# CC2538NF53 register map
File version: 1.0
CPU: CM3 1.0, other endian, MPU, FPU, 3 interrupt priority bits
Registers are 32-bit, read-write, reset 0x0 unless marked. A register's access mark holds for its fields unless they carry their own. Offsets are from the block's base; [hi:lo] are bit positions; {n}, {i} and the like mark numbered series.

## GPTIMER0 — Register fields should be considered static unless otherwise noted as dynamic.
Base 0x40030000
Same registers: GPTIMER1 0x40031000, GPTIMER2 0x40032000, GPTIMER3 0x40033000
0x00 CFG — GPTM configuration This register configures the global operation of the GPTM. The value written to this register determines whether the GPTM is in 32-bit mode (concatenated timers) or in 16-bit mode (individual, split timers).
  [2:0] GPTMCFG — [2:0] GPTM configuration The GPTMCFG values are defined as follows: 0x0: 32-bit timer configuration. 0x1: 32-bit real-time clock 0x2: Reserved 0x3: Reserved 0x4: 16-bit timer configuration. The function is controlled by bits [1:0] of GPTMTAMR and GPTMTBMR. 0x5-0x7: Reserved
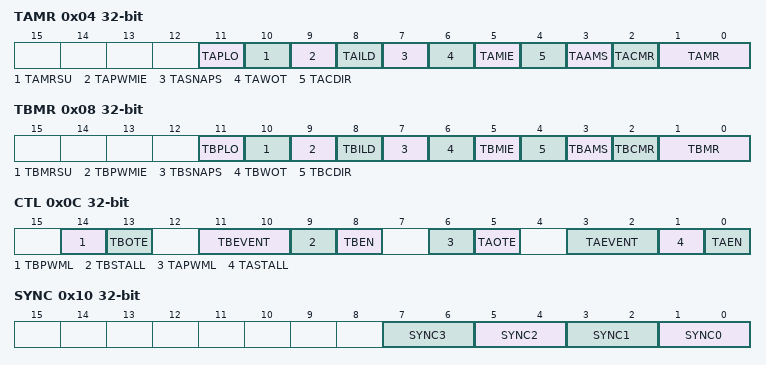
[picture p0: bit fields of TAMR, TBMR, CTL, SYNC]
0x04 TAMR — GPTM Timer A mode This register configures the GPTM based on the configuration selected in the CFG register. This register controls the modes for Timer A when it is used individually. When Timer A and Timer B are concatenated, this register controls the modes for both Timer A and Timer B, and the contents of TBMR are ignored.
  [11] TAPLO — [11:11] Legacy PWM operation 0: Legacy operation 1: CCP is set to 1 on time-out.
  [10] TAMRSU — [10:10] Timer A match register update mode 0: Update GPTMAMATCHR and GPTMAPR if used on the next cycle. 1: Update GPTMAMATCHR and GPTMAPR if used on the next time-out. If the timer is disabled (TAEN is clear) when this bit is set, GPTMTAMATCHR and GPTMTAPR are updated when the timer is enabled. If the timer is stalled (TASTALL is set), GPTMTAMATCHR and GPTMTAPR are updated according to the configuration of this bit.
  [9] TAPWMIE — [9:9] GPTM Timer A PWM interrupt enable This bit enables interrupts in PWM mode on rising, falling, or both edges of the CCP output. 0: Interrupt is disabled. 1: Interrupt is enabled. This bit is valid only in PWM mode.
  [8] TAILD — [8:8] GPTM Timer A PWM interval load write 0: Update the GPTMTAR register with the value in the GPTMTAILR register on the next cycle. If the prescaler is used, update the GPTMTAPS register with the value in the GPTMTAPR register on the next cycle. 1: Update the GPTMTAR register with the value in the GPTMTAILR register on the next cycle. If the prescaler is used, update the GPTMTAPS register with the value in the GPTMTAPR register on the next time-out.
  [7] TASNAPS — [7:7] GPTM Timer A snap-shot mode 0: Snap-shot mode is disabled. 1: If Timer A is configured in periodic mode, the actual free-running value of Timer A is loaded at the time-out event into the GPTM Timer A (GPTMTAR) register.
  [6] TAWOT — [6:6] GPTM Timer A wait-on-trigger 0: Timer A begins counting as soon as it is enabled. 1: If Timer A is enabled (TAEN is set in the GPTMCTL register), Timer A does not begin counting until it receives a trigger from the Timer in the previous position in the daisy-chain. This bit must be clear for GP Timer module 0, Timer A.
  [5] TAMIE — [5:5] GPTM Timer A match interrupt enable 0: The match interrupt is disabled. 1: An interrupt is generated when the match value in the GPTMTAMATCHR register is reached in the one-shot and periodic modes.
  [4] TACDIR — [4:4] GPTM Timer A count direction 0: The timer counts down. 1: The timer counts up. When counting up, the timer starts from a value of 0x0.
  [3] TAAMS — [3:3] GPTM Timer A alternate mode 0: Capture mode is enabled. 1: PWM mode is enabled. Note: To enable PWM mode, the TACM bit must be cleared and the TAMR field must be configured to 0x2.
  [2] TACMR — [2:2] GPTM Timer A capture mode 0: Edge-count mode 1: Edge-time mode
  [1:0] TAMR — [1:0] GPTM Timer A mode 0x0: Reserved 0x1: One-shot mode 0x2: Periodic mode 0x3: Capture mode The timer mode is based on the timer configuration defined by bits [2:0] in the GPTMCFG register.
0x08 TBMR — GPTM Timer B mode This register configures the GPTM based on the configuration selected in the CFG register. This register controls the modes for Timer B when it is used individually. When Timer A and Timer B are concatenated, this register is ignored and TBMR controls the modes for both Timer A and Timer B.
  [11] TBPLO — [11:11] Legacy PWM operation 0: Legacy operation 1: CCP is set to 1 on time-out.
  [10] TBMRSU — [10:10] Timer B match register update mode 0: Update the GPTMBMATCHR and the GPTMBPR, if used on the next cycle. 1: Update the GPTMBMATCHR and the GPTMBPR, if used on the next time-out. If the timer is disabled (TAEN is clear) when this bit is set, GPTMTBMATCHR and GPTMTBPR are updated when the timer is enabled. If the timer is stalled (TBSTALL is set), GPTMTBMATCHR and GPTMTBPR are updated according to the configuration of this bit.
  [9] TBPWMIE — [9:9] GPTM Timer B PWM interrupt enable This bit enables interrupts in PWM mode on rising, falling, or both edges of the CCP output. 0: Interrupt is disabled. 1: Interrupt is enabled. This bit is valid only in PWM mode.
  [8] TBILD — [8:8] GPTM Timer B PWM interval load write 0: Update the GPTMTBR register with the value in the GPTMTBILR register on the next cycle. If the prescaler is used, update the GPTMTBPS register with the value in the GPTMTBPR register on the next cycle. 1: Update the GPTMTBR register with the value in the GPTMTBILR register on the next cycle. If the prescaler is used, update the GPTMTBPS register with the value in the GPTMTBPR register on the next time-out.
  [7] TBSNAPS — [7:7] GPTM Timer B snap-shot mode 0: Snap-shot mode is disabled. 1: If Timer B is configured in the periodic mode, the actual free-running value of Timer A is loaded into the GPTM Timer B (GPTMTBR) register at the time-out event.
  [6] TBWOT — [6:6] GPTM Timer B wait-on-trigger 0: Timer B begins counting as soon as it is enabled. 1: If Timer B is enabled (TBEN is set in the GPTMCTL register), Timer B does not begin counting until it receives a trigger from the timer in the previous position in the daisy-chain.
  [5] TBMIE — [5:5] GPTM Timer B match interrupt enable 0: The match interrupt is disabled. 1: An interrupt is generated when the match value in the GPTMTBMATCHR register is reached in the one-shot and periodic modes.
  [4] TBCDIR — [4:4] GPTM Timer B count direction 0: The timer counts down. 1: The timer counts up. When counting up, the timer starts from a value of 0x0.
  [3] TBAMS — [3:3] GPTM Timer B alternate mode 0: Capture mode is enabled. 1: PWM mode is enabled. Note: To enable PWM mode, the TBCM bit must be cleared and the TBMR field must be configured to 0x2.
  [2] TBCMR — [2:2] GPTM Timer B capture mode 0: Edge-count mode 1: Edge-time mode
  [1:0] TBMR — [1:0] GPTM Timer B mode 0x0: Reserved 0x1: One-shot timer mode 0x2: Periodic timer mode 0x3: Capture mode The timer mode is based on the timer configuration defined by bits [2:0] in the GPTMCFG register.
0x0C CTL — GPTM control This register is used alongside the CFG and TnMR registers to fine-tune the timer configuration, and to enable other features such as timer stall.
  [14] TBPWML — [14:14] GPTM Timer B PWM output level 0: Output is unaffected. 1: Output is inverted.
  [13] TBOTE — [13:13] GPTM Timer B output trigger enable 0: The ADC trigger of output Timer B is disabled. 1: The ADC trigger of output Timer B is enabled.
  [11:10] TBEVENT — [11:10] GPTM Timer B event mode 0x0: Positive edge 0x1: Negative edge 0x2: Reserved 0x3: Both edges
  [9] TBSTALL — [9:9] GPTM Timer B stall enable 0: Timer B continues counting while the processor is halted by the debugger. 1: Timer B freezes counting while the processor is halted by the debugger.
  [8] TBEN — [8:8] GPTM Timer B enable 0: Timer B is disabled. 1: Timer B is enabled and begins counting or the capture logic is enabled based on the GPTMCFG register.
  [6] TAPWML — [6:6] GPTM Timer A PWM output level 0: Output is unaffected. 1: Output is inverted.
  [5] TAOTE — [5:5] GPTM Timer A output trigger enable 0: The ADC trigger of output Timer A is disabled. 1: The ADC trigger of output Timer A is enabled.
  [3:2] TAEVENT — [3:2] GPTM Timer A event mode 0x0: Positive edge 0x1: Negative edge 0x2: Reserved 0x3: Both edges
  [1] TASTALL — [1:1] GPTM Timer A stall enable 0: Timer A continues counting while the processor is halted by the debugger. 1: Timer A freezes counting while the processor is halted by the debugger.
  [0] TAEN — [0:0] GPTM Timer A enable 0: Timer A is disabled. 1: Timer A is enabled and begins counting or the capture logic is enabled based on the GPTMCFG register.
0x10 SYNC — GPTM synchronize Note: This register is implemented on GPTM 0 base address only. This register does however, allow software to synchronize a number of timers.
  [2n+1:2n] SYNC{n} (n=0..3) — [{2n+1}:{2n}] Synchronize GPTM{n} 0x0: GPTM{n} is not affected. 0x1: A time-out event for Timer A of GPTM{n} is triggered. 0x2: A time-out event for Timer B of GPTM{n} is triggered. 0x3: A time-out event for Timer A and Timer B of GPTM{n} is triggered.
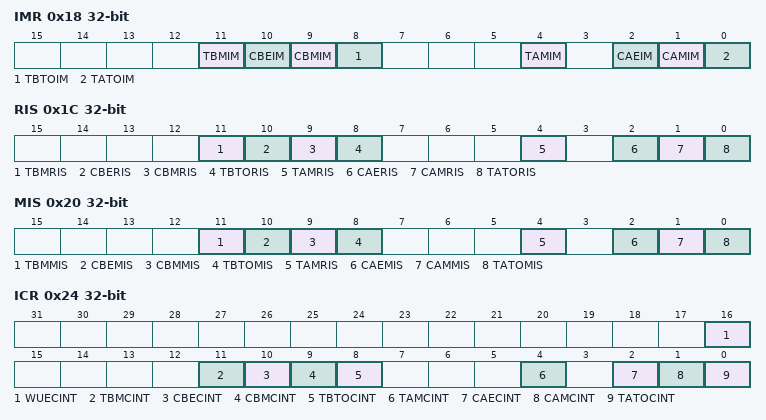
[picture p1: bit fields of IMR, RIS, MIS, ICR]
0x18 IMR — GPTM interrupt mask This register allows software to enable and disable GPTM controller-level interrupts. Setting a bit enables the corresponding interrupt, while clearing a bit disables it.
  [11] TBMIM — [11:11] GPTM Timer B match interrupt mask 0: Interrupt is disabled. 1: Interrupt is enabled.
  [10] CBEIM — [10:10] GPTM Timer B capture event interrupt mask 0: Interrupt is disabled. 1: Interrupt is enabled.
  [9] CBMIM — [9:9] GPTM Timer B capture match interrupt mask 0: Interrupt is disabled. 1: Interrupt is enabled.
  [8] TBTOIM — [8:8] GPTM Timer B time-out interrupt mask 0: Interrupt is disabled. 1: Interrupt is enabled.
  [4] TAMIM — [4:4] GPTM Timer A match interrupt mask 0: Interrupt is disabled. 1: Interrupt is enabled.
  [2] CAEIM — [2:2] GPTM Timer A capture event interrupt mask 0: Interrupt is disabled. 1: Interrupt is enabled.
  [1] CAMIM — [1:1] GPTM Timer A capture match interrupt mask 0: Interrupt is disabled. 1: Interrupt is enabled.
  [0] TATOIM — [0:0] GPTM Timer A time-out interrupt mask 0: Interrupt is disabled. 1: Interrupt is enabled.
0x1C RIS — GPTM raw interrupt status This register shows the state of the GPTM internal interrupt signal. These bits are set whether or not the interrupt is masked in the IMR register. Each bit can be cleared by writing 1 to its corresponding bit in ICR.
  [11] TBMRIS — [11:11] GPTM Timer B match raw interrupt
  [10] CBERIS — [10:10] GPTM Timer B capture event raw interrupt
  [9] CBMRIS — [9:9] GPTM Timer B capture match raw interrupt
  [8] TBTORIS — [8:8] GPTM Timer B time-out raw interrupt
  [4] TAMRIS — [4:4] GPTM Timer A match raw interrupt
  [2] CAERIS — [2:2] GPTM Timer A capture event raw interrupt
  [1] CAMRIS — [1:1] GPTM Timer A capture match raw interrupt
  [0] TATORIS — [0:0] GPTM Timer A time-out raw interrupt
0x20 MIS — GPTM masked interrupt status This register shows the state of the GPTM controller-level interrupt. If an interrupt is unmasked in IMR, and there is an event that causes the interrupt to be asserted, the corresponding bit is set in this register. All bits are cleared by writing 1 to the corresponding bit in ICR.
  [11] TBMMIS — [11:11] GPTM Timer B match masked interrupt
  [10] CBEMIS — [10:10] GPTM Timer B capture event masked interrupt
  [9] CBMMIS — [9:9] GPTM Timer B capture match masked interrupt
  [8] TBTOMIS — [8:8] GPTM Timer B time-out masked interrupt
  [4] TAMRIS — [4:4] GPTM Timer A match raw interrupt
  [2] CAEMIS — [2:2] GPTM Timer A capture event raw interrupt
  [1] CAMMIS — [1:1] GPTM Timer A capture match raw interrupt
  [0] TATOMIS — [0:0] GPTM Timer A time-out raw interrupt
0x24 ICR — GPTM interrupt clear This register is used to clear the status bits in the RIS and MIS registers. Writing 1 to a bit clears the corresponding bit in the RIS and MIS registers.
  [16] WUECINT — [16:16] GPTM write update error interrupt clear
  [11] TBMCINT — [11:11] GPTM Timer B match interrupt clear
  [10] CBECINT — [10:10] GPTM Timer B capture event Interrupt clear
  [9] CBMCINT — [9:9] GPTM Timer B capture match interrupt clear
  [8] TBTOCINT — [8:8] GPTM Timer B time-out interrupt clear
  [4] TAMCINT — [4:4] GPTM Timer A match interrupt clear
  [2] CAECINT — [2:2] GPTM Timer A capture event Interrupt clear
  [1] CAMCINT — [1:1] GPTM Timer A capture match interrupt clear
  [0] TATOCINT — [0:0] GPTM Timer A time-out interrupt clear
0x28 TAILR — GPTM Timer A interval load When the Timer is counting down, this register is used to load the starting count value into the Timer. When the Timer is counting up, this register sets the upper bound for the timeout event. When a GPTM is configured to one of the 32-bit modes, TAILR appears as a 32-bit register (the upper 16-bits correspond to the contents of the GPTM Timer B Interval Load (TBILR) register). In a 16-bit mode, the upper 16 bits of this register read as 0s and have no effect on the state of TBILR.
  [31:0] TAILR — [31:0] GPTM A interval load register
0x2C TBILR — GPTM Timer B interval load When the Timer is counting down, this register is used to load the starting count value into the Timer. When the Timer is counting up, this register sets the upper bound for the time-out event. When a GPTM is configured to one of the 32-bit modes, the contents of bits [15:0] in this register are loaded into the upper 16 bits of the TAILR register. Reads from this register return the current value of Timer B and writes are ignored. In a 16-bit mode, bits [15:0] are used for the load value. Bits [31:16] are reserved in both cases.
  [15:0] TBILR — [15:0] GPTM B interval load register
0x30 TAMATCHR — GPTM Timer A match This register is loaded with a match value. Interrupts can be generated when the Timer value is equal to the value in this register in one-shot or periodic mode. When a GPTM is configured to one of the 32-bit modes, TAMATCHR appears as a 32-bit register (the upper 16-bits correspond to the contents of the GPTM Timer B match (GPTMTBMATCHR) register). In a 16-bit mode, the upper 16 bits of this register read as 0s and have no effect on the state of TBMATCHR.
  [31:0] TAMR — [31:0] GPTM Timer A match register
0x34 TBMATCHR — PTM Timer B match This register is loaded with a match value. Interrupts can be generated when the Timer value is equal to the value in this register in one-shot or periodic mode. When a GPTM is configured to one of the 32-bit modes, the contents of bits [15:0] in this register are loaded into the upper 16 bits of the TAMATCHR register. Reads from this register return the current match value of Timer B and writes are ignored. In a 16-bit mode, bits [15:0] are used for the match value. Bits [31:16] are reserved in both cases.
  [15:0] TBMR — [15:0] GPTM Timer B match register
0x38 TAPR — GPTM Timer A prescale This register allows software to extend the range of the 16-bit Timers in periodic and one-shot modes.
  [7:0] TAPSR — [7:0] GPTM Timer A prescale
0x3C TBPR — GPTM Timer B prescale This register allows software to extend the range of the 16-bit Timers in periodic and one-shot modes.
  [7:0] TBPSR — [7:0] GPTM Timer B prescale
0x40 TAPMR — GPTM Timer A prescale match This register effectively extends the range of TAMATCHR to 24 bits when operating in 16-bit, one-shot or periodic mode.
  [7:0] TAPSR — [7:0] GPTM Timer A prescale match
0x44 TBPMR — GPTM Timer B prescale match This register effectively extends the range ofMTBMATCHR to 24 bits when operating in 16-bit, one-shot or periodic mode.
  [7:0] TBPSR — [7:0] GPTM Timer B prescale match
0x48 TAR — GPTM Timer A This register shows the current value of the Timer A counter. When a GPTM is configured to one of the 32-bit modes, TAR appears as a 32-bit register (the upper 16-bits correspond to the contents of the GPTM Timer B (TBR) register). In the16-bit Input edge count, input edge time, and PWM modes, bits [15:0] contain the value of the counter and bits 23:16 contain the value of the prescaler, which is the upper 8 bits of the count. Bits [31:24] always read as 0. To read the value of the prescaler in 16-bit, one-shot and periodic modes, read bits [23:16] in the TAV register.
  [31:0] TAR — [31:0] GPTM Timer A register
0x4C TBR — GPTM Timer B This register shows the current value of the Timer B counter. When a GPTM is configured to one of the 32-bit modes, the contents of bits [15:0] in this register are loaded into the upper 16 bits of the TAR register. Reads from this register return the current value of Timer B. In a 16-bit mode, bits 15:0 contain the value of the counter and bits [23:16] contain the value of the prescaler in Input edge count, input edge time, and PWM modes, which is the upper 8 bits of the count. Bits [31:24] always read as 0. To read the value of the prescaler in 16-bit, one-shot and periodic modes, read bits [23:16] in the TBV register.
  [15:0] TBR — [15:0] GPTM Timer B register
0x50 TAV — GPTM Timer A value When read, this register shows the current, free-running value of Timer A in all modes. Software can use this value to determine the time elapsed between an interrupt and the ISR entry when using the snapshot feature with the periodic operating mode. When written, the value written into this register is loaded into the TAR register on the next clock cycle. When a GPTM is configured to one of the 32-bit modes, TAV appears as a 32-bit register (the upper 16-bits correspond to the contents of the GPTM Timer B Value (TBV) register). In a 16-bit mode, bits [15:0] contain the value of the counter and bits [23:16] contain the current, free-running value of the prescaler, which is the upper 8 bits of the count in input edge count, input edge time, PWM and one-shot or periodic up count modes. In one-shot or periodic down count modes, the prescaler stored in [23:16] is a true prescaler, meaning bits [23:16] count down before decrementing the value in bits [15:0]. The prescaler its [31:24] always read as 0.
  [31:0] TAV — [31:0] GPTM Timer A register
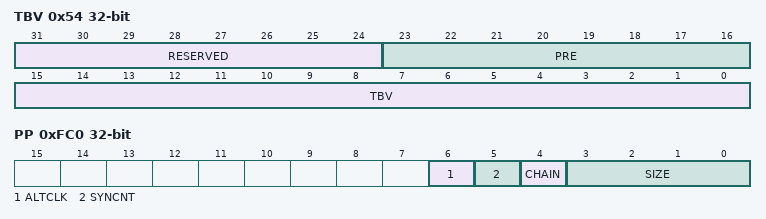
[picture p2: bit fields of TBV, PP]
0x54 TBV — GPTM Timer B value When read, this register shows the current, free-running value of Timer B in all modes. Software can use this value to determine the time elapsed between an interrupt and the ISR entry. When written, the value written into this register is loaded into the TBR register on the next clock cycle. When a GPTM is configured to one of the 32-bit modes, the contents of bits 15:0 in this register are loaded into the upper 16 bits of the TAV register. Reads from this register return the current free-running value of Timer B. In a 16-bit mode, bits [15:0] contain the value of the counter and bits [23:16] contain the current, free-running value of the prescaler, which is the upper 8 bits of the count in input edge count, input edge time, PWM and one-shot or periodic up count modes. In one-shot or periodic down count modes, the prescaler stored in [23:16] is a true prescaler, meaning bits [23:16] count down before decrementing the value in bits [15:0]. The prescaler its [31:24] always read as 0.
  [31:24] RESERVED — [31:24] GPTM Timer B register
  [23:16] PRE — [23:16] GPTM Timer B prescale register (16-bit mode)
  [15:0] TBV — [15:0] GPTM Timer B register
0x5C TAPS — GPTM Timer A prescale snapshot For the 32-bit wide GPTM, this register shows the current value of the Timer A prescaler in the 32-bit modes. This register is ununsed in 16-bit GPTM mode.
  [15:0] PSS — [15:0] GPTM Timer A prescaler
0x60 TBPS — GPTM Timer B prescale snapshot For the 32-bit wide GPTM, this register shows the current value of the Timer B prescaler in the 32-bit modes. This register is ununsed in 16-bit GPTM mode.
  [15:0] PSS — [15:0] GPTM Timer B prescaler
0x64 TAPV — GPTM Timer A prescale value For the 32-bit wide GPTM, this register shows the current free-running value of the Timer A prescaler in the 32-bit modes. Software can use this value in conjunction with the TAV register to determine the time elapsed between an interrupt and the ISR entry. This register is ununsed in 16- or 32-bit GPTM mode.
  [15:0] PSV — [15:0] GPTM Timer A prescaler value
0x68 TBPV — GPTM Timer B prescale value For the 32-bit wide GPTM, this register shows the current free-running value of the Timer B prescaler in the 32-bit modes. Software can use this value in conjunction with the TBV register to determine the time elapsed between an interrupt and the ISR entry. This register is ununsed in 16- or 32-bit GPTM mode.
  [15:0] PSV — [15:0] GPTM Timer B prescaler value
0xFC0 PP — GPTM peripheral properties The PP register provides information regarding the properties of the general-purpose Timer module.
  [6] ALTCLK — [6:6] Alternate clock source 0: Timer is not capable of using an alternate clock. 1: Timer is capable of using an alternate clock.
  [5] SYNCNT — [5:5] Synchronized start 0: Timer is not capable of synchronizing the count value with other timers. 1: Timer is capable of synchronizing the count value with other timers.
  [4] CHAIN — [4:4] Chain with other timers 0: Timer is not capable of chaining with previously numbered Timers. 1: Timer is capable of chaining with previously numbered timers.
  [3:0] SIZE — [3:0] Timer size 0: Timer A and Timer B are 16 bits wide with 8-bit prescale. 1: Timer A and Timer B are 32 bits wide with 16-bit prescale.
